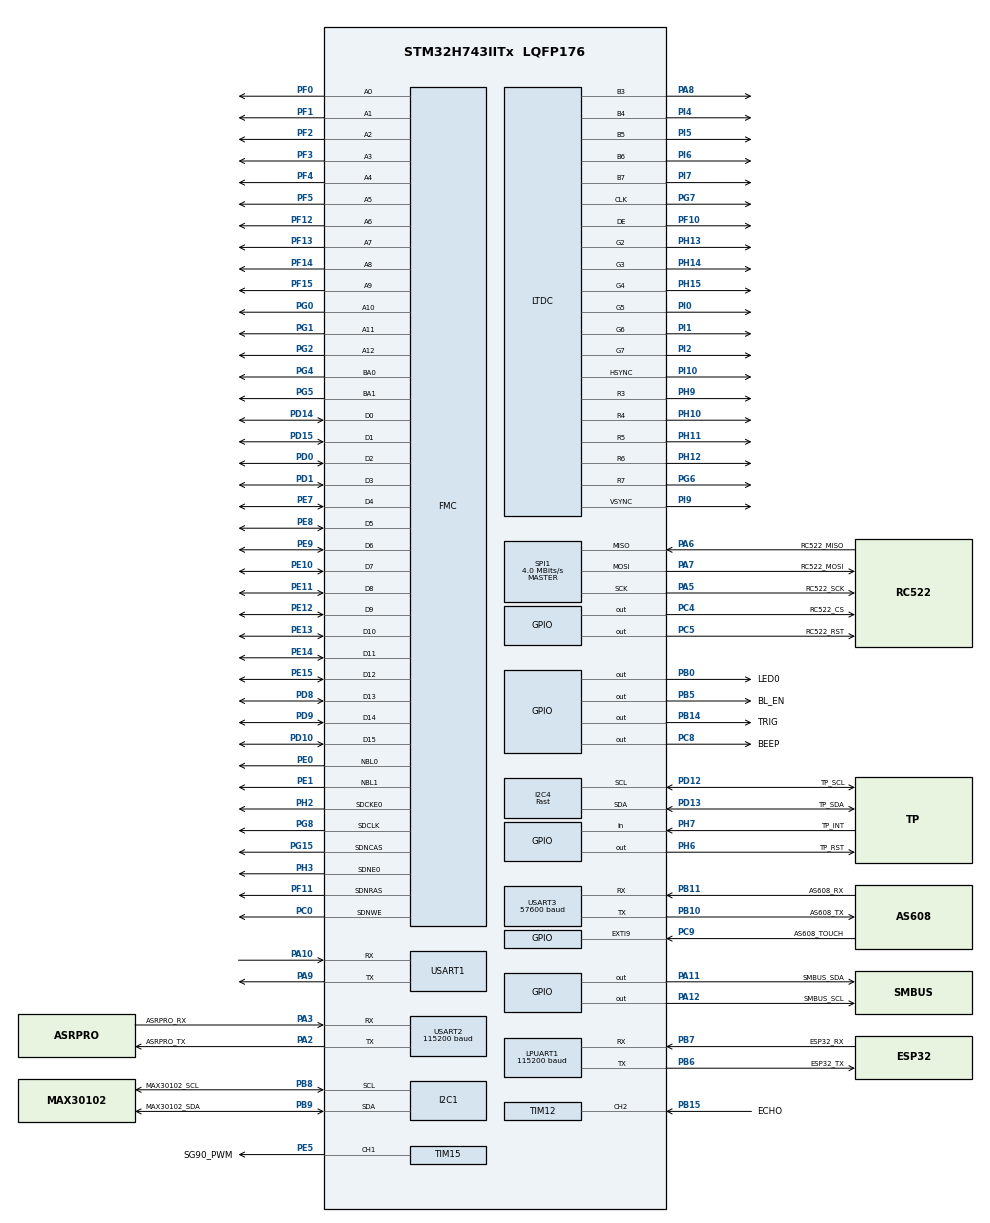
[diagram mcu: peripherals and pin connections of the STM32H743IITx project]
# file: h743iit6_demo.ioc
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CORTEX_M7.BaseAddress_S-Cortex_Memory_Protection_Unit_Region1_Settings_S=0x38000000
CORTEX_M7.BaseAddress_Spec=0x24000000
CORTEX_M7.CPU_DCache=Enabled
CORTEX_M7.CPU_ICache=Enabled
CORTEX_M7.DisableExec_Spec=MPU_INSTRUCTION_ACCESS_ENABLE
CORTEX_M7.Enable_S-Cortex_Memory_Protection_Unit_Region1_Settings_S=MPU_REGION_ENABLE
CORTEX_M7.IsBufferable_Spec=MPU_ACCESS_BUFFERABLE
CORTEX_M7.IsCacheable_S-Cortex_Memory_Protection_Unit_Region1_Settings_S=MPU_ACCESS_CACHEABLE
CORTEX_M7.IsCacheable_Spec=MPU_ACCESS_CACHEABLE
CORTEX_M7.IsShareable_Spec=MPU_ACCESS_NOT_SHAREABLE
CORTEX_M7.Size_S-Cortex_Memory_Protection_Unit_Region1_Settings_S=MPU_REGION_SIZE_64KB
CORTEX_M7.Size_Spec=MPU_REGION_SIZE_512KB
CORTEX_M7.SubRegionDisable_Spec=0x0
CORTEX_M7.TypeExtField_Spec=MPU_TEX_LEVEL1
CORTEX_M7.default_mode_Activation=1
DMA2D.ColorMode=DMA2D_OUTPUT_RGB565
DMA2D.InputColorModeForeground=DMA2D_INPUT_RGB565
DMA2D.Mode=DMA2D_M2M
FMC.CASLatency1=FMC_SDRAM_CAS_LATENCY_3
FMC.ColumnBitsNumber1=FMC_SDRAM_COLUMN_BITS_NUM_9
FMC.ExitSelfRefreshDelay1=8
FMC.LoadToActiveDelay1=2
FMC.RCDDelay1=2
FMC.RPDelay1=2
FMC.RPDelay2=2
FMC.ReadBurst1=FMC_SDRAM_RBURST_ENABLE
FMC.ReadBurst2=FMC_SDRAM_RBURST_ENABLE
FMC.ReadPipeDelay1=FMC_SDRAM_RPIPE_DELAY_1
FMC.ReadPipeDelay2=FMC_SDRAM_RPIPE_DELAY_1
FMC.RowCycleDelay1=7
FMC.RowCycleDelay2=7
FMC.SDClockPeriod1=FMC_SDRAM_CLOCK_PERIOD_2
FMC.SDClockPeriod2=FMC_SDRAM_CLOCK_PERIOD_2
FMC.SelfRefreshTime1=6
FMC.WriteRecoveryTime1=5
FREERTOS.Tasks01=defaultTask,24,640,StartDefaultTask,Default,NULL,Dynamic,NULL,NULL
FREERTOS.configCHECK_FOR_STACK_OVERFLOW=2
FREERTOS.configENABLE_FPU=1
FREERTOS.configGENERATE_RUN_TIME_STATS=1
FREERTOS.configRECORD_STACK_HIGH_ADDRESS=1
FREERTOS.configUSE_MALLOC_FAILED_HOOK=1
FREERTOS.configUSE_STATS_FORMATTING_FUNCTIONS=1
FREERTOS.configUSE_TICK_HOOK=1
I2C1.Timing=0x307075B1
I2C4.I2C_Speed_Mode=I2C_Fast
I2C4.Timing=0x00B03FDB
LPUART1.BaudRate=115200
LTDC.ActiveH=480
LTDC.ActiveW=800
LTDC.Alpha_L0=255
LTDC.Alpha_L1=255
LTDC.Blue_L0=0
LTDC.FBStartAdress_L0=0xC0000000
LTDC.FBStartAdress_L1=0xC012C000
LTDC.Green_L0=255
LTDC.HBP=88
LTDC.HFP=40
LTDC.HSync=48
LTDC.ImageHeight_L0=480
LTDC.ImageHeight_L1=600
LTDC.ImageWidth_L0=800
LTDC.Layers=0
LTDC.PixelFormat_L0=LTDC_PIXEL_FORMAT_RGB565
LTDC.Red_L1=255
LTDC.VBP=32
LTDC.VFP=13
LTDC.VSync=3
LTDC.WindowX0_L1=0
LTDC.WindowX1_L0=800
LTDC.WindowX1_L1=1024
LTDC.WindowY0_L1=0
LTDC.WindowY1_L0=480
LTDC.WindowY1_L1=600
Mcu.Family=STM32H7
Mcu.Name=STM32H743IITx
Mcu.Package=LQFP176
NVIC.DMA2D_IRQn=true\:5\:0\:false\:false\:true\:true\:true\:true\:true
NVIC.EXTI9_5_IRQn=true\:5\:0\:false\:false\:true\:true\:true\:true\:true
NVIC.LPUART1_IRQn=true\:5\:0\:false\:false\:true\:true\:true\:true\:true
NVIC.LTDC_IRQn=true\:5\:0\:false\:false\:true\:true\:true\:true\:true
NVIC.PriorityGroup=NVIC_PRIORITYGROUP_4
NVIC.TIM16_IRQn=true\:5\:0\:false\:false\:true\:true\:true\:true\:true
NVIC.TIM8_BRK_TIM12_IRQn=true\:5\:0\:false\:false\:true\:true\:true\:true\:true
NVIC.TIM8_TRG_COM_TIM14_IRQn=true\:5\:0\:false\:false\:true\:true\:true\:true\:true
NVIC.TIM8_UP_TIM13_IRQn=true\:5\:0\:true\:false\:true\:false\:false\:true\:true
NVIC.TimeBase=TIM8_UP_TIM13_IRQn
NVIC.TimeBaseIP=TIM8
NVIC.USART3_IRQn=true\:5\:0\:false\:false\:true\:true\:true\:true\:true
PA10.Mode=Asynchronous
PA10.PinAttribute=Free
PA10.Signal=USART1_RX
PA11.GPIO_Label=SMBUS_SDA
PA11.GPIO_ModeDefaultOutputPP=GPIO_MODE_OUTPUT_OD
PA11.GPIO_PuPd=GPIO_NOPULL
PA11.GPIO_Speed=GPIO_SPEED_FREQ_HIGH
PA11.PinState=GPIO_PIN_SET
PA11.Signal=GPIO_Output
PA12.GPIO_Label=SMBUS_SCL
PA12.GPIO_ModeDefaultOutputPP=GPIO_MODE_OUTPUT_OD
PA12.GPIO_PuPd=GPIO_NOPULL
PA12.GPIO_Speed=GPIO_SPEED_FREQ_HIGH
PA12.PinState=GPIO_PIN_SET
PA12.Signal=GPIO_Output
PA13\ (JTMS/SWDIO).Mode=Serial_Wire
PA13\ (JTMS/SWDIO).PinAttribute=Free
PA13\ (JTMS/SWDIO).Signal=DEBUG_JTMS-SWDIO
PA14\ (JTCK/SWCLK).Mode=Serial_Wire
PA14\ (JTCK/SWCLK).PinAttribute=Free
PA14\ (JTCK/SWCLK).Signal=DEBUG_JTCK-SWCLK
PA2.GPIO_Label=ASRPRO_TX
PA2.Mode=Asynchronous
PA2.PinAttribute=Free
PA2.Signal=USART2_TX
PA3.GPIO_Label=ASRPRO_RX
PA3.Mode=Asynchronous
PA3.PinAttribute=Free
PA3.Signal=USART2_RX
PA5.GPIO_Label=RC522_SCK
PA5.Mode=Full_Duplex_Master
PA5.PinAttribute=Free
PA5.Signal=SPI1_SCK
PA6.GPIO_Label=RC522_MISO
PA6.Mode=Full_Duplex_Master
PA6.PinAttribute=Free
PA6.Signal=SPI1_MISO
PA7.GPIO_Label=RC522_MOSI
PA7.Mode=Full_Duplex_Master
PA7.PinAttribute=Free
PA7.Signal=SPI1_MOSI
PA8.GPIO_Speed=GPIO_SPEED_FREQ_VERY_HIGH
PA8.Mode=RGB565
PA8.PinAttribute=Free
PA8.Signal=LTDC_B3
PA9.Mode=Asynchronous
PA9.PinAttribute=Free
PA9.Signal=USART1_TX
PB0.GPIO_Label=LED0
PB0.PinAttribute=Free
PB0.Signal=GPIO_Output
PB10.GPIO_Label=AS608_TX
PB10.Mode=Asynchronous
PB10.PinAttribute=Free
PB10.Signal=USART3_TX
PB11.GPIO_Label=AS608_RX
PB11.Mode=Asynchronous
PB11.PinAttribute=Free
PB11.Signal=USART3_RX
PB14.GPIO_Label=TRIG
PB14.GPIO_PuPd=GPIO_PULLUP
PB14.GPIO_Speed=GPIO_SPEED_FREQ_HIGH
PB14.PinAttribute=Free
PB14.Signal=GPIO_Output
PB15.GPIO_Label=ECHO
PB15.PinAttribute=Free
PB15.Signal=S_TIM12_CH2
PB5.GPIO_Label=BL_EN
PB5.GPIO_PuPd=GPIO_PULLUP
PB5.PinState=GPIO_PIN_SET
PB5.Signal=GPIO_Output
PB6.GPIO_Label=ESP32_TX
PB6.Mode=Asynchronous
PB6.Signal=LPUART1_TX
PB7.GPIO_Label=ESP32_RX
PB7.Mode=Asynchronous
PB7.Signal=LPUART1_RX
PB8.GPIO_Label=MAX30102_SCL
PB8.Mode=I2C
PB8.Signal=I2C1_SCL
PB9.GPIO_Label=MAX30102_SDA
PB9.Mode=I2C
PB9.Signal=I2C1_SDA
PC0.PinAttribute=Free
PC0.Signal=FMC_SDNWE
PC4.GPIO_Label=RC522_CS
PC4.PinAttribute=Free
PC4.PinState=GPIO_PIN_SET
PC4.Signal=GPIO_Output
PC5.GPIO_Label=RC522_RST
PC5.PinAttribute=Free
PC5.PinState=GPIO_PIN_SET
PC5.Signal=GPIO_Output
PC8.GPIO_Label=BEEP
PC8.Signal=GPIO_Output
PC9.GPIO_Label=AS608_TOUCH
PC9.PinAttribute=Free
PC9.Signal=GPXTI9
PD0.PinAttribute=Free
PD0.Signal=FMC_D2_DA2
PD1.Signal=FMC_D3_DA3
PD10.PinAttribute=Free
PD10.Signal=FMC_D15_DA15
PD12.GPIO_Label=TP_SCL
PD12.GPIO_Pu=GPIO_PULLUP
PD12.Mode=I2C
PD12.PinAttribute=Free
PD12.Signal=I2C4_SCL
PD13.GPIO_Label=TP_SDA
PD13.GPIO_Pu=GPIO_PULLUP
PD13.Mode=I2C
PD13.PinAttribute=Free
PD13.Signal=I2C4_SDA
PD14.PinAttribute=Free
PD14.Signal=FMC_D0_DA0
PD15.PinAttribute=Free
PD15.Signal=FMC_D1_DA1
PD8.PinAttribute=Free
PD8.Signal=FMC_D13_DA13
PD9.PinAttribute=Free
PD9.Signal=FMC_D14_DA14
PE0.Signal=FMC_NBL0
PE1.Signal=FMC_NBL1
PE10.PinAttribute=Free
PE10.Signal=FMC_D7_DA7
PE11.PinAttribute=Free
PE11.Signal=FMC_D8_DA8
PE12.PinAttribute=Free
PE12.Signal=FMC_D9_DA9
PE13.PinAttribute=Free
PE13.Signal=FMC_D10_DA10
PE14.PinAttribute=Free
PE14.Signal=FMC_D11_DA11
PE15.PinAttribute=Free
PE15.Signal=FMC_D12_DA12
PE5.GPIO_Label=SG90_PWM
PE5.PinAttribute=Free
PE5.Signal=S_TIM15_CH1
PE7.PinAttribute=Free
PE7.Signal=FMC_D4_DA4
PE8.PinAttribute=Free
PE8.Signal=FMC_D5_DA5
PE9.PinAttribute=Free
PE9.Signal=FMC_D6_DA6
PF0.PinAttribute=Free
PF0.Signal=FMC_A0
PF1.PinAttribute=Free
PF1.Signal=FMC_A1
PF10.GPIO_Speed=GPIO_SPEED_FREQ_VERY_HIGH
PF10.Mode=RGB565
PF10.PinAttribute=Free
PF10.Signal=LTDC_DE
PF11.PinAttribute=Free
PF11.Signal=FMC_SDNRAS
PF12.PinAttribute=Free
PF12.Signal=FMC_A6
PF13.PinAttribute=Free
PF13.Signal=FMC_A7
PF14.PinAttribute=Free
PF14.Signal=FMC_A8
PF15.PinAttribute=Free
PF15.Signal=FMC_A9
PF2.PinAttribute=Free
PF2.Signal=FMC_A2
PF3.PinAttribute=Free
PF3.Signal=FMC_A3
PF4.PinAttribute=Free
PF4.Signal=FMC_A4
PF5.Signal=FMC_A5
PG0.PinAttribute=Free
PG0.Signal=FMC_A10
PG1.PinAttribute=Free
PG1.Signal=FMC_A11
PG15.Signal=FMC_SDNCAS
PG2.PinAttribute=Free
PG2.Signal=FMC_A12
PG4.PinAttribute=Free
PG4.Signal=FMC_A14_BA0
PG5.PinAttribute=Free
PG5.Signal=FMC_A15_BA1
PG6.GPIO_Speed=GPIO_SPEED_FREQ_VERY_HIGH
PG6.Mode=RGB565
PG6.Signal=LTDC_R7
PG7.GPIO_Speed=GPIO_SPEED_FREQ_VERY_HIGH
PG7.Mode=RGB565
PG7.Signal=LTDC_CLK
PG8.Signal=FMC_SDCLK
PH0-OSC_IN\ (PH0).Mode=HSE-External-Oscillator
PH0-OSC_IN\ (PH0).PinAttribute=Free
PH0-OSC_IN\ (PH0).Signal=RCC_OSC_IN
PH1-OSC_OUT\ (PH1).Mode=HSE-External-Oscillator
PH1-OSC_OUT\ (PH1).PinAttribute=Free
PH1-OSC_OUT\ (PH1).Signal=RCC_OSC_OUT
PH10.GPIO_Speed=GPIO_SPEED_FREQ_VERY_HIGH
PH10.Mode=RGB565
PH10.PinAttribute=Free
PH10.Signal=LTDC_R4
PH11.GPIO_Speed=GPIO_SPEED_FREQ_VERY_HIGH
PH11.Mode=RGB565
PH11.PinAttribute=Free
PH11.Signal=LTDC_R5
PH12.GPIO_Speed=GPIO_SPEED_FREQ_VERY_HIGH
PH12.Mode=RGB565
PH12.PinAttribute=Free
PH12.Signal=LTDC_R6
PH13.GPIO_Speed=GPIO_SPEED_FREQ_VERY_HIGH
PH13.Mode=RGB565
PH13.PinAttribute=Free
PH13.Signal=LTDC_G2
PH14.GPIO_Speed=GPIO_SPEED_FREQ_VERY_HIGH
PH14.Mode=RGB565
PH14.PinAttribute=Free
PH14.Signal=LTDC_G3
PH15.GPIO_Speed=GPIO_SPEED_FREQ_VERY_HIGH
PH15.Mode=RGB565
PH15.PinAttribute=Free
PH15.Signal=LTDC_G4
PH2.Mode=SdramChipSelect1_1
PH2.PinAttribute=Free
PH2.Signal=FMC_SDCKE0
PH3.Mode=SdramChipSelect1_1
PH3.PinAttribute=Free
PH3.Signal=FMC_SDNE0
PH6.GPIO_Label=TP_RST
PH6.GPIO_PuPd=GPIO_PULLUP
PH6.PinAttribute=Free
PH6.Signal=GPIO_Output
PH7.GPIO_Label=TP_INT
PH7.GPIO_PuPd=GPIO_NOPULL
PH7.PinAttribute=Free
PH7.Signal=GPIO_Input
PH9.GPIO_Speed=GPIO_SPEED_FREQ_VERY_HIGH
PH9.Mode=RGB565
PH9.PinAttribute=Free
PH9.Signal=LTDC_R3
PI0.GPIO_Speed=GPIO_SPEED_FREQ_VERY_HIGH
PI0.Mode=RGB565
PI0.PinAttribute=Free
PI0.Signal=LTDC_G5
PI1.GPIO_Speed=GPIO_SPEED_FREQ_VERY_HIGH
PI1.Mode=RGB565
PI1.PinAttribute=Free
PI1.Signal=LTDC_G6
PI10.GPIO_Speed=GPIO_SPEED_FREQ_VERY_HIGH
PI10.Mode=RGB565
PI10.PinAttribute=Free
PI10.Signal=LTDC_HSYNC
PI2.GPIO_Speed=GPIO_SPEED_FREQ_VERY_HIGH
PI2.Mode=RGB565
PI2.PinAttribute=Free
PI2.Signal=LTDC_G7
PI4.GPIO_Speed=GPIO_SPEED_FREQ_VERY_HIGH
PI4.Mode=RGB565
PI4.Signal=LTDC_B4
PI5.GPIO_Speed=GPIO_SPEED_FREQ_VERY_HIGH
PI5.Mode=RGB565
PI5.Signal=LTDC_B5
PI6.GPIO_Speed=GPIO_SPEED_FREQ_VERY_HIGH
PI6.Mode=RGB565
PI6.Signal=LTDC_B6
PI7.GPIO_Speed=GPIO_SPEED_FREQ_VERY_HIGH
PI7.Mode=RGB565
PI7.Signal=LTDC_B7
PI9.GPIO_Speed=GPIO_SPEED_FREQ_VERY_HIGH
PI9.Mode=RGB565
PI9.PinAttribute=Free
PI9.Signal=LTDC_VSYNC
ProjectManager.HeapSize=0x200
ProjectManager.StackSize=0x400
ProjectManager.TargetToolchain=CMake
RCC.ADCFreq_Value=262500000
RCC.APB1Freq_Value=120000000
RCC.APB2Freq_Value=120000000
RCC.APB3Freq_Value=120000000
RCC.APB4Freq_Value=120000000
RCC.CortexFreq_Value=480000000
RCC.D1PPRE=RCC_APB3_DIV2
RCC.D2PPRE1=RCC_APB1_DIV2
RCC.D2PPRE2=RCC_APB2_DIV2
RCC.D3PPRE=RCC_APB4_DIV2
RCC.DIVM1=5
RCC.DIVM2=16
RCC.DIVM3=2
RCC.DIVN1=192
RCC.DIVN2=336
RCC.DIVN3=72
RCC.DIVR2=3
RCC.DIVR3=45
RCC.FMCCLockSelection=RCC_FMCCLKSOURCE_PLL2
RCC.HCLKFreq_Value=240000000
RCC.HPRE=RCC_HCLK_DIV2
RCC.PLL1_VCI_Range-AdvancedSettings=RCC_PLL1VCIRANGE_0
RCC.PLL2FRACN=0
RCC.PLL3FRACN=0
RCC.PLLFRACN=0
RCC.PLLSourceVirtual=RCC_PLLSOURCE_HSE
RCC.SPI123CLockSelection=RCC_SPI123CLKSOURCE_CLKP
RCC.SYSCLKFreq_VALUE=480000000
RCC.SYSCLKSource=RCC_SYSCLKSOURCE_PLLCLK
RCC.USBFreq_Value=480000000
SH.FMC_A0.0=FMC_A0,13b-sda1
SH.FMC_A1.0=FMC_A1,13b-sda1
SH.FMC_A10.0=FMC_A10,13b-sda1
SH.FMC_A11.0=FMC_A11,13b-sda1
SH.FMC_A12.0=FMC_A12,13b-sda1
SH.FMC_A14_BA0.0=FMC_BA0,FourSdramBanks1
SH.FMC_A15_BA1.0=FMC_BA1,FourSdramBanks1
SH.FMC_A2.0=FMC_A2,13b-sda1
SH.FMC_A3.0=FMC_A3,13b-sda1
SH.FMC_A4.0=FMC_A4,13b-sda1
SH.FMC_A5.0=FMC_A5,13b-sda1
SH.FMC_A6.0=FMC_A6,13b-sda1
SH.FMC_A7.0=FMC_A7,13b-sda1
SH.FMC_A8.0=FMC_A8,13b-sda1
SH.FMC_A9.0=FMC_A9,13b-sda1
SH.FMC_D0_DA0.0=FMC_D0,sd-16b-d1
SH.FMC_D10_DA10.0=FMC_D10,sd-16b-d1
SH.FMC_D11_DA11.0=FMC_D11,sd-16b-d1
SH.FMC_D12_DA12.0=FMC_D12,sd-16b-d1
SH.FMC_D13_DA13.0=FMC_D13,sd-16b-d1
SH.FMC_D14_DA14.0=FMC_D14,sd-16b-d1
SH.FMC_D15_DA15.0=FMC_D15,sd-16b-d1
SH.FMC_D1_DA1.0=FMC_D1,sd-16b-d1
SH.FMC_D2_DA2.0=FMC_D2,sd-16b-d1
SH.FMC_D3_DA3.0=FMC_D3,sd-16b-d1
SH.FMC_D4_DA4.0=FMC_D4,sd-16b-d1
SH.FMC_D5_DA5.0=FMC_D5,sd-16b-d1
SH.FMC_D6_DA6.0=FMC_D6,sd-16b-d1
SH.FMC_D7_DA7.0=FMC_D7,sd-16b-d1
SH.FMC_D8_DA8.0=FMC_D8,sd-16b-d1
SH.FMC_D9_DA9.0=FMC_D9,sd-16b-d1
SH.FMC_NBL0.0=FMC_NBL0,Sd2ByteEnable1
SH.FMC_NBL1.0=FMC_NBL1,Sd2ByteEnable1
SH.FMC_SDCLK.0=FMC_SDCLK,13b-sda1
SH.FMC_SDNCAS.0=FMC_SDNCAS,13b-sda1
SH.FMC_SDNRAS.0=FMC_SDNRAS,13b-sda1
SH.FMC_SDNWE.0=FMC_SDNWE,13b-sda1
SH.S_TIM12_CH2.0=TIM12_CH2,Input_Capture2_from_TI2
SH.S_TIM15_CH1.0=TIM15_CH1,PWM Generation1 CH1
SPI1.BaudRatePrescaler=SPI_BAUDRATEPRESCALER_16
SPI1.CalculateBaudRate=4.0 MBits/s
SPI1.DataSize=SPI_DATASIZE_8BIT
SPI1.Direction=SPI_DIRECTION_2LINES
SPI1.Mode=SPI_MODE_MASTER
SPI1.VirtualType=VM_MASTER
TIM12.AutoReloadPreload=TIM_AUTORELOAD_PRELOAD_ENABLE
TIM12.Channel-Input_Capture2_from_TI2=TIM_CHANNEL_2
TIM12.Period=65535
TIM12.Prescaler=200-1
TIM14.Period=100-1
TIM14.Prescaler=480-1
TIM15.Channel-PWM\ Generation1\ CH1=TIM_CHANNEL_1
TIM15.Period=200-1
TIM15.Prescaler=24000-1
TIM16.Period=1000-1
TIM16.Prescaler=480-1
TIM17.Prescaler=480-1
USART1.VirtualMode-Asynchronous=VM_ASYNC
USART2.BaudRate=115200
USART2.VirtualMode-Asynchronous=VM_ASYNC
USART3.BaudRate=57600
USART3.VirtualMode-Asynchronous=VM_ASYNC
VP_DMA2D_VS_DMA2D.Mode=DMA2D_Activate
VP_FREERTOS_VS_CMSIS_V2.Mode=CMSIS_V2
VP_MEMORYMAP_VS_MEMORYMAP.Mode=CurAppReg
VP_SYS_VS_tim8.Mode=TIM8
VP_TIM12_VS_ClockSourceINT.Mode=Internal
VP_TIM14_VS_ClockSourceINT.Mode=Enable_Timer
VP_TIM15_VS_ClockSourceINT.Mode=Internal
VP_TIM16_VS_ClockSourceINT.Mode=Enable_Timer
VP_TIM17_VS_ClockSourceINT.Mode=Enable_Timer
board=custom

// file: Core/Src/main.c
/* USER CODE BEGIN Header */
/**
 ******************************************************************************
 * @file           : main.c
 * @brief          : Main program body
 ******************************************************************************
 * @attention
 *
 * Copyright (c) 2025 STMicroelectronics.
 * All rights reserved.
 *
 * This software is licensed under terms that can be found in the LICENSE file
 * in the root directory of this software component.
 * If no LICENSE file comes with this software, it is provided AS-IS.
 *
 ******************************************************************************
 */
/* USER CODE END Header */
#include "main.h"
#include "cmsis_os.h"
#include "dma2d.h"
#include "i2c.h"
#include "usart.h"
#include "ltdc.h"
#include "memorymap.h"
#include "spi.h"
#include "tim.h"
#include "gpio.h"
#include "fmc.h"

/* USER CODE BEGIN Includes */
#include <stdio.h>
#include "bsp_sdram.h"
#include "atk_rgblcd.h"
#include "lvgl.h"
// #include "lv_demos.h"
#include "lv_port_disp.h"
#include "lv_port_indev.h"
#include "bsp_esp32.h"
#include "FreeRTOS.h"
#include "task.h"
#include "cmsis_os.h"
#include "semphr.h"
#include "bsp_sr04.h"

/* USER CODE END Includes */

/* USER CODE BEGIN PV */
uint16_t LCD_BUFFER[480][800] __attribute__((__section__(".lcd_buf")));

/* USER CODE END PV */

void SystemClock_Config(void);
void PeriphCommonClock_Config(void);
static void MPU_Config(void);
void MX_FREERTOS_Init(void);

int main(void)
{

  /* MPU Configuration--------------------------------------------------------*/
  MPU_Config();

  /* Enable the CPU Cache */

  /* Enable I-Cache---------------------------------------------------------*/
  SCB_EnableICache();

  /* Enable D-Cache---------------------------------------------------------*/
  SCB_EnableDCache();

  /* MCU Configuration--------------------------------------------------------*/

  /* Reset of all peripherals, Initializes the Flash interface and the Systick. */
  HAL_Init();

  /* Configure the system clock */
  SystemClock_Config();

  /* Configure the peripherals common clocks */
  PeriphCommonClock_Config();

  /* Initialize all configured peripherals */
  MX_GPIO_Init();
  MX_LTDC_Init();
  MX_FMC_Init();
  MX_USART1_UART_Init();
  MX_DMA2D_Init();
  MX_TIM17_Init();
  MX_I2C4_Init();
  MX_TIM16_Init();
  MX_TIM14_Init();
  MX_SPI1_Init();
  MX_TIM12_Init();
  MX_USART2_UART_Init();
  MX_USART3_UART_Init();
  MX_TIM15_Init();
  MX_LPUART1_UART_Init();
  MX_I2C1_Init();
  /* USER CODE BEGIN 2 */
    HAL_TIM_Base_Start_IT(&htim16);
    HAL_TIM_Base_Start_IT(&htim14);
    MX_FMC_Init();
    MY_SDRAM_Init();
    MX_LTDC_Init();

  /* USER CODE END 2 */

  /* Init scheduler */
  osKernelInitialize();

  /* Call init function for freertos objects (in cmsis_os2.c) */
  MX_FREERTOS_Init();

  /* Start scheduler */
  osKernelStart();

  /* We should never get here as control is now taken by the scheduler */

  /* Infinite loop */
    while (1) {

    /* USER CODE BEGIN 3 */
        HAL_GPIO_TogglePin(LED0_GPIO_Port, LED0_Pin);
        HAL_Delay(1000);

        // memset(LCD_BUFFER, 0XCC, sizeof(LCD_BUFFER) / 2);
        // HAL_Delay(1000);
        // memset(LCD_BUFFER, 0XDD, sizeof(LCD_BUFFER) / 2);
        // HAL_Delay(1000);
        // uint8_t rx[2] = {0x11, 0x22};
        // HAL_UART_Transmit(&hlpuart1, rx, 2, 1000);
        // HAL_Delay(1000);
        // lv_task_handler();
        // HAL_Delay(5);

        // uint8_t line_num = 5;
        // for (int i = 0; i < 480; i++) {
        //     for (int j = 0; j < line_num; j++) {
        //         int      width = 800 / line_num;
        //         uint16_t color = 0;
        //         switch (j % 6) {
        //             case 0: color = 0x0000; break;
        //             case 1: color = 0x7f00; break;
        //             case 2: color = 0xff00; break;
        //             case 3: color = 0x7f7f; break;
        //             case 4: color = 0x00ff; break;
        //             case 5: color = 0x007f; break;
        //         }

        //         for (int k = width * j; k < width * (j + 1); k++) {
        //             LCD_BUFFER[i][k] = color;
        //         }
        //     }
        // }
    }
  /* USER CODE END 3 */
}

void SystemClock_Config(void)
{
  RCC_OscInitTypeDef RCC_OscInitStruct = {0};
  RCC_ClkInitTypeDef RCC_ClkInitStruct = {0};

  /** Supply configuration update enable
  */
  HAL_PWREx_ConfigSupply(PWR_LDO_SUPPLY);

  /** Configure the main internal regulator output voltage
  */
  __HAL_PWR_VOLTAGESCALING_CONFIG(PWR_REGULATOR_VOLTAGE_SCALE0);

  while(!__HAL_PWR_GET_FLAG(PWR_FLAG_VOSRDY)) {}

  /** Initializes the RCC Oscillators according to the specified parameters
  * in the RCC_OscInitTypeDef structure.
  */
  RCC_OscInitStruct.OscillatorType = RCC_OSCILLATORTYPE_HSI|RCC_OSCILLATORTYPE_HSE;
  RCC_OscInitStruct.HSEState = RCC_HSE_ON;
  RCC_OscInitStruct.HSIState = RCC_HSI_DIV1;
  RCC_OscInitStruct.HSICalibrationValue = RCC_HSICALIBRATION_DEFAULT;
  RCC_OscInitStruct.PLL.PLLState = RCC_PLL_ON;
  RCC_OscInitStruct.PLL.PLLSource = RCC_PLLSOURCE_HSE;
  RCC_OscInitStruct.PLL.PLLM = 5;
  RCC_OscInitStruct.PLL.PLLN = 192;
  RCC_OscInitStruct.PLL.PLLP = 2;
  RCC_OscInitStruct.PLL.PLLQ = 2;
  RCC_OscInitStruct.PLL.PLLR = 2;
  RCC_OscInitStruct.PLL.PLLRGE = RCC_PLL1VCIRANGE_2;
  RCC_OscInitStruct.PLL.PLLVCOSEL = RCC_PLL1VCOWIDE;
  RCC_OscInitStruct.PLL.PLLFRACN = 0;
  if (HAL_RCC_OscConfig(&RCC_OscInitStruct) != HAL_OK)
  {
    Error_Handler();
  }

  /** Initializes the CPU, AHB and APB buses clocks
  */
  RCC_ClkInitStruct.ClockType = RCC_CLOCKTYPE_HCLK|RCC_CLOCKTYPE_SYSCLK
                              |RCC_CLOCKTYPE_PCLK1|RCC_CLOCKTYPE_PCLK2
                              |RCC_CLOCKTYPE_D3PCLK1|RCC_CLOCKTYPE_D1PCLK1;
  RCC_ClkInitStruct.SYSCLKSource = RCC_SYSCLKSOURCE_PLLCLK;
  RCC_ClkInitStruct.SYSCLKDivider = RCC_SYSCLK_DIV1;
  RCC_ClkInitStruct.AHBCLKDivider = RCC_HCLK_DIV2;
  RCC_ClkInitStruct.APB3CLKDivider = RCC_APB3_DIV2;
  RCC_ClkInitStruct.APB1CLKDivider = RCC_APB1_DIV2;
  RCC_ClkInitStruct.APB2CLKDivider = RCC_APB2_DIV2;
  RCC_ClkInitStruct.APB4CLKDivider = RCC_APB4_DIV2;

  if (HAL_RCC_ClockConfig(&RCC_ClkInitStruct, FLASH_LATENCY_4) != HAL_OK)
  {
    Error_Handler();
  }
}

void PeriphCommonClock_Config(void)
{
  RCC_PeriphCLKInitTypeDef PeriphClkInitStruct = {0};

  /** Initializes the peripherals clock
  */
  PeriphClkInitStruct.PeriphClockSelection = RCC_PERIPHCLK_CKPER;
  PeriphClkInitStruct.CkperClockSelection = RCC_CLKPSOURCE_HSI;
  if (HAL_RCCEx_PeriphCLKConfig(&PeriphClkInitStruct) != HAL_OK)
  {
    Error_Handler();
  }
}

 /* MPU Configuration */

void MPU_Config(void)
{
  MPU_Region_InitTypeDef MPU_InitStruct = {0};

  /* Disables the MPU */
  HAL_MPU_Disable();

  /** Initializes and configures the Region and the memory to be protected
  */
  MPU_InitStruct.Enable = MPU_REGION_ENABLE;
  MPU_InitStruct.Number = MPU_REGION_NUMBER0;
  MPU_InitStruct.BaseAddress = 0x24000000;
  MPU_InitStruct.Size = MPU_REGION_SIZE_512KB;
  MPU_InitStruct.SubRegionDisable = 0x0;
  MPU_InitStruct.TypeExtField = MPU_TEX_LEVEL1;
  MPU_InitStruct.AccessPermission = MPU_REGION_NO_ACCESS;
  MPU_InitStruct.DisableExec = MPU_INSTRUCTION_ACCESS_ENABLE;
  MPU_InitStruct.IsShareable = MPU_ACCESS_NOT_SHAREABLE;
  MPU_InitStruct.IsCacheable = MPU_ACCESS_CACHEABLE;
  MPU_InitStruct.IsBufferable = MPU_ACCESS_BUFFERABLE;

  HAL_MPU_ConfigRegion(&MPU_InitStruct);

  /** Initializes and configures the Region and the memory to be protected
  */
  MPU_InitStruct.Number = MPU_REGION_NUMBER1;
  MPU_InitStruct.BaseAddress = 0x38000000;
  MPU_InitStruct.Size = MPU_REGION_SIZE_64KB;
  MPU_InitStruct.TypeExtField = MPU_TEX_LEVEL0;
  MPU_InitStruct.IsBufferable = MPU_ACCESS_NOT_BUFFERABLE;

  HAL_MPU_ConfigRegion(&MPU_InitStruct);
  /* Enables the MPU */
  HAL_MPU_Enable(MPU_PRIVILEGED_DEFAULT);

}

void HAL_TIM_PeriodElapsedCallback(TIM_HandleTypeDef *htim)
{
  if (htim->Instance == TIM8) {
    HAL_IncTick();
  }
  /* USER CODE BEGIN Callback 1 */
    if (htim->Instance == TIM16) {
        // lv_tick_inc(1);
    }

    if (htim->Instance == TIM14) {
        extern volatile uint32_t CPU_RunTime;

        CPU_RunTime++; // 更新计数值
    }

  /* USER CODE END Callback 1 */
}

void Error_Handler(void)
{
    __disable_irq();
    while (1) {
    }
}

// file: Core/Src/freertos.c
/* USER CODE BEGIN Header */
/**
 ******************************************************************************
 * File Name          : freertos.c
 * Description        : Code for freertos applications
 ******************************************************************************
 * @attention
 *
 * Copyright (c) 2025 STMicroelectronics.
 * All rights reserved.
 *
 * This software is licensed under terms that can be found in the LICENSE file
 * in the root directory of this software component.
 * If no LICENSE file comes with this software, it is provided AS-IS.
 *
 ******************************************************************************
 */
/* USER CODE END Header */

#include "FreeRTOS.h"
#include "task.h"
#include "main.h"
#include "cmsis_os.h"

/* USER CODE BEGIN Includes */
#include "lvgl.h"
#include "semphr.h"
// #include "lv_demos.h"
#include "lv_port_disp.h"
#include "lv_port_indev.h"
#include "tim.h"
#include "bsp_sg90.h"
#include "bsp_rc522.h"
#include "bsp_as608.h"
#include "bsp_sr04.h"
#include "bsp_mlx90614.h"
#include "bsp_esp32.h"
#include "gui_guider.h"
#include "events_init.h"
#include "bsp_cmd.h"
#include "blood.h"
#include "guider_customer_fonts.h"
#include <stdio.h>

/* USER CODE END Includes */

/* USER CODE BEGIN Variables */
/* FreeRTOS变量 */
static BaseType_t  xHigherPriorityTaskWoken = pdFALSE;
EventGroupHandle_t DoorEventGroup;
QueueHandle_t      ESP32Queue;
TaskHandle_t       AS608_Task_Handle;
SemaphoreHandle_t  MutexSemaphore; /* lv_task_handler()线程不安全必须加互斥量 */

/* 普通变量 */
Attributes_T      attributes;
lv_ui             guider_ui;
volatile uint32_t CPU_RunTime       = 0;
static uint8_t    ESP32_RX_BUF[100] = {0};
char              message[100];
// static uint8_t     ESP32_Val         = CMD_RESTART;
// uint8_t            unum              = 0;
static uint8_t cmd         = CMD_GET_INIT;
static uint8_t message_num = 0;

/* USER CODE END Variables */
/* Definitions for defaultTask */
osThreadId_t defaultTaskHandle;
const osThreadAttr_t defaultTask_attributes = {
  .name = "defaultTask",
  .stack_size = 640 * 4,
  .priority = (osPriority_t) osPriorityNormal,
};

/* USER CODE BEGIN FunctionPrototypes */
void Start_Task(void *pvParameters);
void LVGL_Task(void *pvParameters);

/* USER CODE END FunctionPrototypes */

void StartDefaultTask(void *argument);

void MX_FREERTOS_Init(void); /* (MISRA C 2004 rule 8.1) */

/* Hook prototypes */
void configureTimerForRunTimeStats(void);
unsigned long getRunTimeCounterValue(void);
void vApplicationTickHook(void);
void vApplicationStackOverflowHook(xTaskHandle xTask, signed char *pcTaskName);
void vApplicationMallocFailedHook(void);

/* USER CODE BEGIN 1 */
/* Functions needed when configGENERATE_RUN_TIME_STATS is on */
__weak void configureTimerForRunTimeStats(void)
{
    CPU_RunTime = 0ul;
}

__weak unsigned long getRunTimeCounterValue(void)
{
    return CPU_RunTime;
}
/* USER CODE END 1 */

/* USER CODE BEGIN 3 */
void vApplicationTickHook(void)
{
    /* This function will be called by each tick interrupt if
    configUSE_TICK_HOOK is set to 1 in FreeRTOSConfig.h. User code can be
    added here, but the tick hook is called from an interrupt context, so
    code must not attempt to block, and only the interrupt safe FreeRTOS API
    functions can be used (those that end in FromISR()). */
    lv_tick_inc(1);
}
/* USER CODE END 3 */

/* USER CODE BEGIN 4 */
void vApplicationStackOverflowHook(xTaskHandle xTask, signed char *pcTaskName)
{
    /* Run time stack overflow checking is performed if
    configCHECK_FOR_STACK_OVERFLOW is defined to 1 or 2. This hook function is
    called if a stack overflow is detected. */
    printf("Stack overflow in task: %s\n", pcTaskName);
}
/* USER CODE END 4 */

/* USER CODE BEGIN 5 */
void vApplicationMallocFailedHook(void)
{
    /* vApplicationMallocFailedHook() will only be called if
    configUSE_MALLOC_FAILED_HOOK is set to 1 in FreeRTOSConfig.h. It is a hook
    function that will get called if a call to pvPortMalloc() fails.
    pvPortMalloc() is called internally by the kernel whenever a task, queue,
    timer or semaphore is created. It is also called by various parts of the
    demo application. If heap_1.c or heap_2.c are used, then the size of the
    heap available to pvPortMalloc() is defined by configTOTAL_HEAP_SIZE in
    FreeRTOSConfig.h, and the xPortGetFreeHeapSize() API function can be used
    to query the size of free heap space that remains (although it does not
    provide information on how the remaining heap might be fragmented). */
    printf("Malloc Failed\n");
}
/* USER CODE END 5 */

void MX_FREERTOS_Init(void) {

  /* Create the thread(s) */
  /* creation of defaultTask */
  defaultTaskHandle = osThreadNew(StartDefaultTask, NULL, &defaultTask_attributes);

  /* USER CODE BEGIN RTOS_THREADS */
    /* add threads, ... */
    /* 创建启动任务 */
    xTaskCreate((TaskFunction_t)Start_Task, "Start_Task", 450, NULL, osPriorityNormal, NULL);

  /* USER CODE END RTOS_THREADS */

}

void StartDefaultTask(void *argument)
{
  /* USER CODE BEGIN StartDefaultTask */
    // char pcTaskInfo[300]; /* 用于保存任务状态信息 */
    lv_init();
    lv_port_disp_init();
    lv_port_indev_init();
    // lv_demo_stress();
    setup_ui(&guider_ui);
    events_init(&guider_ui);
    // lv_demo_widgets();
    HAL_GPIO_WritePin(AS608_TOUCH_GPIO_Port, AS608_TOUCH_Pin, GPIO_PIN_RESET);
    HAL_UARTEx_ReceiveToIdle_IT(&ESP32_UART, ESP32_RX_BUF, sizeof(ESP32_RX_BUF));
    HAL_UART_Transmit(&ESP32_UART, &cmd, 1, HAL_MAX_DELAY);

    /* Infinite loop */
    for (;;) {
        //   vTaskGetRunTimeStats(pcTaskInfo);
        //   printf("Task Name\tRun Time\tpercent\t \r\n");
        //   printf("%s\r\n", pcTaskInfo);
        // blood_Loop(&dis_hr_valid, &dis_spo2_valid);1

        if (attributes.alarm) {
            Beep_ON();
            HAL_GPIO_TogglePin(LED0_GPIO_Port, LED0_Pin);
            vTaskDelay(500);
            Beep_OFF();
            vTaskDelay(500);
        } else {
            // uint8_t temp[4] = {0xB6, 0x00, 0x41, 0x5A};
            // HAL_UART_Transmit(&ESP32_UART, temp, sizeof(temp), HAL_MAX_DELAY);
            HAL_GPIO_TogglePin(LED0_GPIO_Port, LED0_Pin);
            vTaskDelay(500);
        }
    }
  /* USER CODE END StartDefaultTask */
}

/* USER CODE BEGIN Application */
/**
 * @brief   LVGL任务
 * @param   pvParameters: 任务参数
 * @retval  无
 */
void LVGL_Task(void *pvParameters)
{
    while (1) {
        xSemaphoreTake(MutexSemaphore, portMAX_DELAY);
        lv_task_handler();
        xSemaphoreGive(MutexSemaphore);
        vTaskDelay(4);
    }
}

/**
 * @brief   开始任务
 * @param   pvParameters: 任务参数
 * @retval  无
 */
void Start_Task(void *pvParameters)
{
    BaseType_t xReturn;

    /* 初始化 */
    SG90_Init();
    RC522_Init();
    // MAX30102_Init();
    // MAX30102_GET_Init();
    // Max30102_reset();
    // MAX30102_Config();
    AS608_Init();
    SMBus_Init();
    // HAL_UART_Transmit(&ESP32_UART, &ESP32_Val, 1, HAL_MAX_DELAY);
    // HAL_UART_Receive(&ESP32_UART, &ESP32_Val, 1, HAL_MAX_DELAY);
    // while (ESP32_Val != CMD_RESTART_OK);
    // printf("ESP32 restart OK\n");

    // HAL_UART_Receive(&ESP32_UART, &unum, 1, HAL_MAX_DELAY);
    // printf("unum: %d\n", unum);

    // uint8_t TempUID[4] = {0xA5, 0x29, 0xF6, 0x04};
    // RegisterCard(TempUID);

    /* 创建事件组 */
    DoorEventGroup = xEventGroupCreate();
    if (DoorEventGroup == NULL) {
        // 处理事件组创建失败的情况
        printf("Failed to create DoorEventGroup\n");
        printf("Press reset to restart\n");
        while (1);
    }

    /* 创建队列 */
    ESP32Queue = xQueueCreate(1, sizeof(uint8_t));
    if (ESP32Queue == NULL) {
        printf("Failed to create ESP32Queue\n");
        printf("Press reset to restart\n");
        while (1);
    }

    /* 创建LVGL互斥锁 */
    MutexSemaphore = xSemaphoreCreateMutex();
    if (MutexSemaphore == NULL) {
        printf("Failed to create MutexSemaphore\n");
        printf("Press reset to restart\n");
        while (1);
    }

    /* 创建LVGL任务 */
    xReturn = xTaskCreate((TaskFunction_t)LVGL_Task, "LVGL_Task", 800, NULL, osPriorityNormal + 1, NULL);
    if (xReturn != pdPASS) {
        // 处理任务创建失败的情况
        printf("Failed to create LVGL_Task\n");
        printf("press reset to restart\n");
    }

    /* 创建SG90舵机任务 */
    xReturn = xTaskCreate((TaskFunction_t)SG90_Task, "SG90_Task", 70, NULL, osPriorityNormal, NULL);
    if (xReturn != pdPASS) {
        // 处理任务创建失败的情况
        printf("Failed to create SG90_Task\n");
        printf("press reset to restart\n");
    }

    /* 创建RC522读卡器任务 */
    xReturn = xTaskCreate((TaskFunction_t)RC522_Task, "RC522_Task", 200, NULL, osPriorityNormal, NULL);
    if (xReturn != pdPASS) {
        // 处理任务创建失败的情况
        printf("Failed to create RC522_Task\n");
        printf("press reset to restart\n");
    }

    /* 创建AS608指纹识别任务 */
    xReturn = xTaskCreate((TaskFunction_t)AS608_Task, "AS608_Task", 150, NULL, osPriorityNormal, &AS608_Task_Handle);
    if (xReturn != pdPASS) {
        // 处理任务创建失败的情况
        printf("Failed to create AS608_Task\n");
        printf("press reset to restart\n");
    }

    /* 创建ESP32任务 */
    xReturn = xTaskCreate((TaskFunction_t)ESP32_Task, "ESP32_Task", 200, NULL, osPriorityNormal, NULL);
    if (xReturn != pdPASS) {
        // 处理任务创建失败的情况
        printf("Failed to create ESP32_Task\n");
        printf("press reset to restart\n");
    }

    /* 创建SR04超声波任务 */
    xReturn = xTaskCreate((TaskFunction_t)SR04_Task, "SR04_Task", 380, NULL, osPriorityNormal, NULL);
    if (xReturn != pdPASS) {
        // 处理任务创建失败的情况
        printf("Failed to create SR04_Task\n");
        printf("press reset to restart\n");
    }

    /* 自杀 */
    vTaskDelete(NULL);
}

void HAL_GPIO_EXTI_Callback(uint16_t GPIO_Pin)
{
    /* 进入临界段，临界段可以嵌套 */
    uint32_t ulReturn = taskENTER_CRITICAL_FROM_ISR();

    if (GPIO_Pin == AS608_TOUCH_Pin) {
        xTaskNotifyFromISR(AS608_Task_Handle, AS608_TASK_BIT, eSetBits, &xHigherPriorityTaskWoken);
        // xEventGroupSetBitsFromISR(DoorEventGroup, AS608_TASK_BIT, &xHigherPriorityTaskWoken);
        printf("Finger Touch\n");
    }

    /* 退出临界段 */
    taskEXIT_CRITICAL_FROM_ISR(ulReturn);

    /* 如果有更高优先级的任务被唤醒，则进行上下文切换 */
    portYIELD_FROM_ISR(xHigherPriorityTaskWoken);
}

void HAL_UARTEx_RxEventCallback(UART_HandleTypeDef *huart, uint16_t Size)
{
    /* 进入临界段，临界段可以嵌套 */
    uint32_t ulReturn = taskENTER_CRITICAL_FROM_ISR();

    /* 串口接收不定长数据 */
    if (huart == &AS608_UART) {
        extern SemaphoreHandle_t AS608Semphore;

        xSemaphoreGiveFromISR(AS608Semphore, &xHigherPriorityTaskWoken);

        /* 必须再调用HAL_UARTEx_ReceiveToIdle_IT函数，否则只会接收数据一次 */
        HAL_UARTEx_ReceiveToIdle_IT(&AS608_UART, AS608_RX_BUF, sizeof(AS608_RX_BUF));
    }

    if (huart == &ESP32_UART) {
        if (Size == 1) {
            xQueueSendToBackFromISR(ESP32Queue, ESP32_RX_BUF, &xHigherPriorityTaskWoken);
        } else if (Size == 5) {
            if (ESP32_RX_BUF[0] == CMD_RECEIVE_UID) {
                RegisterCard(ESP32_RX_BUF + 1);
            } else if (ESP32_RX_BUF[0] == CMD_RECEIVE_WEATHER) {
                memcpy(attributes.weather, ESP32_RX_BUF + 1, Size - 1);
                attributes.weather[Size] = '\0'; // 添加空终止符
                printf("weather: %s\n", attributes.weather);
                lv_label_set_text(guider_ui.main_label_weather, attributes.weather);
            }
        } else {
            switch (ESP32_RX_BUF[0]) {
                case CMD_RECEIVE_CALL:
                    // memcpy(attributes.call, ESP32_RX_BUF + 1, Size - 1);
                    // attributes.call[Size] = '\0'; // 添加空终止符
                    attributes.call = ESP32_RX_BUF[1];
                    printf("call: %d\n", attributes.call);
                    break;
                case CMD_RECEIVE_ALARM:
                    // memcpy(attributes.alarm, ESP32_RX_BUF + 1, Size - 1);
                    // attributes.alarm[Size] = '\0'; // 添加空终止符
                    attributes.alarm = ESP32_RX_BUF[1];
                    printf("alarm: %d\n", attributes.alarm);
                    break;
                case CMD_RECEIVE_VISITORS:
                    attributes.visitors = ESP32_RX_BUF[1];
                    printf("visitors: %d\n", attributes.visitors);
                    lv_label_set_text_fmt(guider_ui.main_label_visitor, "%d 人", attributes.visitors);
                    break;
                case CMD_RECEIVE_WEATHER:
                    memcpy(attributes.weather, ESP32_RX_BUF + 1, Size - 1);
                    attributes.weather[Size] = '\0'; // 添加空终止符
                    printf("weather: %s\n", attributes.weather);
                    lv_label_set_text(guider_ui.main_label_weather, attributes.weather);
                    break;
                case CMD_RECEIVE_TEMPERATURE:
                    attributes.temperature = ESP32_RX_BUF[1];
                    printf("weather temperature: %d\n", attributes.temperature);
                    lv_label_set_text_fmt(guider_ui.main_label_weather_tem, "%d C", attributes.temperature);
                    break;
                case CMD_LEAVE_MESSAGE:
                    memcpy(message, ESP32_RX_BUF + 1, Size - 1);
                    message[Size] = '\0';
                    printf("message: %s\n", message);
                    switch (message_num++) {
                        case 0: lv_label_set_text(guider_ui.main_label_message_1, message); break;
                        case 1: lv_label_set_text(guider_ui.main_label_message_2, message); break;
                        case 2: lv_label_set_text(guider_ui.main_label_message_3, message); break;
                        case 3: lv_label_set_text(guider_ui.main_label_message_4, message); break;
                        case 4: lv_label_set_text(guider_ui.main_label_message_5, message); break;
                        case 5: lv_label_set_text(guider_ui.main_label_message_6, message); break;
                        case 6: lv_label_set_text(guider_ui.main_label_message_7, message); break;
                        case 7: lv_label_set_text(guider_ui.main_label_message_8, message); break;
                        default: break;
                    }
                    break;
                default: printf("\nReceive String: %s", ESP32_RX_BUF); break;
            }
        }

        HAL_UARTEx_ReceiveToIdle_IT(&ESP32_UART, ESP32_RX_BUF, sizeof(ESP32_RX_BUF));
    }

    /* 退出临界段 */
    taskEXIT_CRITICAL_FROM_ISR(ulReturn);

    /* 如果有更高优先级的任务被唤醒，则进行上下文切换 */
    portYIELD_FROM_ISR(xHigherPriorityTaskWoken);
}

void HAL_TIM_IC_CaptureCallback(TIM_HandleTypeDef *htim)
{
    /* 进入临界段，临界段可以嵌套 */
    uint32_t ulReturn = taskENTER_CRITICAL_FROM_ISR();

    if (htim == &SR04_TIM) // 判断触发的中断的定时器为SR04_TIM
    {
        extern uint8_t  measure_Cnt;
        extern uint32_t measure_Buf[3];

        switch (measure_Cnt) {
            case 1:
                measure_Buf[0] = HAL_TIM_ReadCapturedValue(&SR04_TIM, SR04_CHANNEL); // 获取当前的捕获值.
                __HAL_TIM_SET_CAPTUREPOLARITY(&SR04_TIM, SR04_CHANNEL,
                                              TIM_ICPOLARITY_FALLING); // 设置为下降沿捕获
                measure_Cnt++;
                break;
            case 2:
                measure_Buf[1] = HAL_TIM_ReadCapturedValue(&SR04_TIM, SR04_CHANNEL); // 获取当前的捕获值.
                HAL_TIM_IC_Stop_IT(&SR04_TIM,
                                   SR04_CHANNEL); // 停止捕获   或者: __HAL_TIM_DISABLE(&SR04_TIM);
                measure_Cnt++;
        }
    }

    /* 退出临界段 */
    taskEXIT_CRITICAL_FROM_ISR(ulReturn);

    /* 如果有更高优先级的任务被唤醒，则进行上下文切换 */
    portYIELD_FROM_ISR(xHigherPriorityTaskWoken);
}

int _write(int fd, char *pBuffer, int size)
{
    for (int i = 0; i < size; i++) {
        while ((USART1->ISR & 0X40) == 0); // 等待上一次串口数据发送完成
        USART1->TDR = (uint8_t)pBuffer[i]; // 写TDR,串口将发送数据
    }
    return size;
}

/* USER CODE END Application */
